# PIC32CZ2051CA80176 register map
Vendor: Microchip Technology; Series: PIC32CZCA80; File version: 0
CPU: CM7 r1p1, little endian, MPU, FPU, double-precision FPU, I-cache, D-cache, ITCM, DTCM, 3 interrupt priority bits, 222 interrupts
Registers are 32-bit, read-write, reset 0x0 unless marked. A register's access mark holds for its fields unless they carry their own. Offsets are from the block's base; [hi:lo] are bit positions; 'fields as' and 'values as' point back to an identical list.

## SUPC — Supply Controller
Base 0x44020000
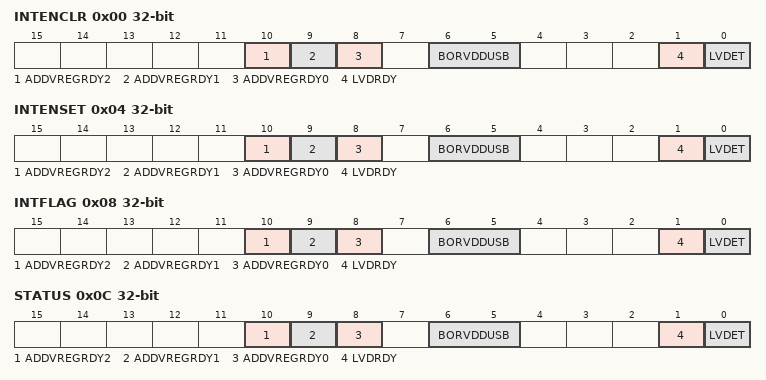
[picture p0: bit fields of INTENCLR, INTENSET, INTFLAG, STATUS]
0x00 INTENCLR write-1-clears — Interrupt Enable Clear
  [10] ADDVREGRDY2 — Additional Regulator ready 2 Interrupt Enable
  [9] ADDVREGRDY1 — Additional Regulator ready 1 Interrupt Enable
  [8] ADDVREGRDY0 — Additional Regulator ready 0 Interrupt Enable
  [6:5] BORVDDUSB — BORVDDUSB Interrupt Enable
  [1] LVDRDY — Low Voltage Detector Ready Interrupt Enable
  [0] LVDET — Low Voltage Detector Interrupt Enable
0x04 INTENSET write-1-sets — Interrupt Enable Set
  fields as INTENCLR
0x08 INTFLAG write-1-clears — Interrupt Flag Status and Clear
  [10] ADDVREGRDY2 — Additional Regulator ready 2 Interrupt. Set to one if additionnal regulator is ready meaning that output voltage is correct.
  [9] ADDVREGRDY1 — Additional Regulator ready 1 Interrupt. Set to one if additionnal regulator is ready meaning that output voltage is correct.
  [8] ADDVREGRDY0 — Additional Regulator ready 0 Interrupt. Set to one if additionnal regulator is ready meaning that output voltage is correct.
  [6:5] BORVDDUSB — BORVDDUSB Interrupt. Set to one if VDDUSB issue is detected.
  [1] LVDRDY — Low Voltage Detector Ready Interrupt. Set to one if LVD is ready to operate.
  [0] LVDET — Low Voltage Detector Interrupt. Set to one if VDDIO crosses the treshold voltage in the good direction according to LVD.DIR.
0x0C STATUS ro — Flag status
  [10] ADDVREGRDY2 — Additional Regulator ready 2 Status. One if voltage is OK. It corresponds to vreg_ready_mv signal of additional regulator.
  [9] ADDVREGRDY1 — Additional Regulator ready 1 Status. One if voltage is OK. It corresponds to vreg_ready_mv signal of additional regulator.
  [8] ADDVREGRDY0 — Additional Regulator ready 0 Status. One if voltage is OK. It corresponds to vreg_ready_mv signal of additional regulator.
  [6:5] BORVDDUSB — BORVDDUSB Status. One if VDDUSB is OK. It corresponds to bor_vddusb_n_mv signal of SMOR.
  [1] LVDRDY — Low Voltage Detector Ready Status
  [0] LVDET — Low Voltage Detector Status.
0x10 SYNCBUSY ro — Synchronisation Busy
  [0] BOR — BOR Synchronization Busy
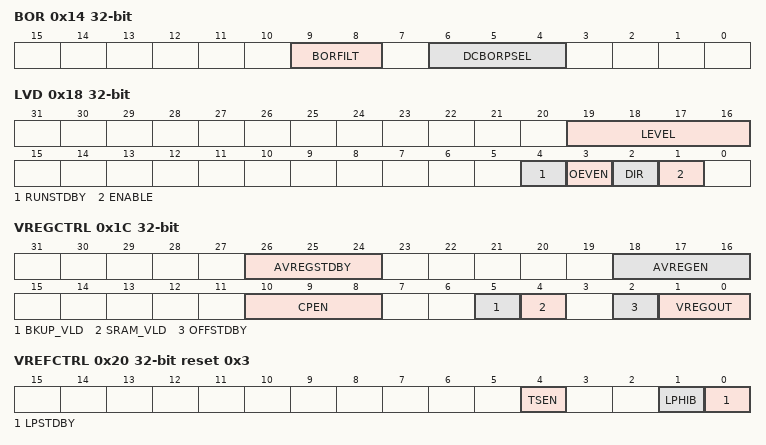
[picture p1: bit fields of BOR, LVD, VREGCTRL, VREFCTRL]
0x14 BOR — BOR Control
  [9:8] BORFILT — BOR filtering
    0=NOFILT (No digital filtering); 1=FILT32US (32us filtering); 2=FILT125US (125us filtering); 3=FILT250US (250us filtering)
  [6:4] DCBORPSEL — Duty Cycle BOR Prescaler Select
    0=NODIV (Not Divided); 1=DIV2 (Divide clock by 2); 2=DIV4 (Divide clock by 4); 3=DIV8 (Divide clock by 8); 4=DIV16 (Divide clock by 16); 5=DIV32 (Divide clock by 32); 6=DIV64 (Divide clock by 64); 7=DIV128 (Divide clock by 128)
0x18 LVD — LVD Control
  [19:16] LEVEL — Threshold Level. See 'pwr_smor_[nn]_v1 DOS' - level section to get details.
  [4] RUNSTDBY — Run during Standby
  [3] OEVEN — Output Event Enable
  [2] DIR — Direction
    0=Rising detection; 1=Falling detection
  [1] ENABLE
0x1C VREGCTRL — VREG Control
  [26:24] AVREGSTDBY — Additional Voltage Regulator Configuration
    0=OFFINSTDBY (Regulator is OFF while in sleep mode equal or deeper than standby mode. It is OFF in hibernate and backup mode as well.); 1=ONINSTDBY (Regulator is ON in Standby mode if AVREGEN bit is set. is OFF from Hibernate mode. It is OFF in backup mode as well.)
  [18:16] AVREGEN — Additional Voltage Regulator Enable
  [10:8] CPEN — Charge Pump Enable and Auto-enable.
  [5] BKUP_VLD — Backup Valid Status Bit
  [4] SRAM_VLD — SRAM Valid Status Bit
  [2] OFFSTDBY — Off in Standby Control for VREGSW[N-1]. Useful for Riverside only.
    0=OFF (In standby mode, VREGSW1,2,3 are OFF); 1=ON (In standby mode, VREGSW1,2,3 are ON)
  [1:0] VREGOUT — VREG Output Control in RUN mode only. Enable by production fuse by CALSUPC.VREGOUTEN
    0=1p2v (In Active mode, VDDCORE_RAM, VDDCORE_BU, VDDCORE_SW and optionnaly VDDCORE_PLL USB are set to 1.2v.); 1=1p0v (In Active mode, VDDCORE_RAM, VDDCORE_BU, VDDCORE_SW and optionnaly VDDCORE_PLL USB are set to 1.0v.); 2=0p8v (In Active mode, VDDCORE_RAM, VDDCORE_BU, VDDCORE_SW and optionnaly VDDCORE_PLL USB are set to 0.8v.)
0x20 VREFCTRL reset 0x3 — VREF Control
  [4] TSEN — Temperature Sensor Output Enable
  [1] LPHIB — Bandgap and Regulators Low Power Hibernate Enable
    0=FullPower (In hibernate mode, bandgap is set to nominal power mode. As a consequence, enabled regulator(s) are set to nominal power mode.); 1=LowPower (In hibernate mode, bandgap is set to low power mode. As a consequence, enabled regulator(s) are set to low power mode.)
  [0] LPSTDBY — Bandgap and Regulators Low Power Standby Enable
    0=FullPower (In standby mode, bandgap and enabled regulator(s) are set to nominal power mode.); 1=LowPower (In standby mode, bandgap and enabled regulator(s) are set to low power mode.)
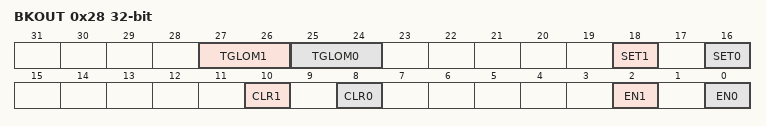
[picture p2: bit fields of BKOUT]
0x28 BKOUT — Backup Output Control
  [27:26] TGLOM1 — Toggle Output Mode
    0=DISABLE (The output does not toggle.); 1=RTCTGL (The output toggles on RTC event.); 2=BKUPTGL (The output is set when the device enters backup mode or battery backup mode. The output should then be cleared by software.)
  [25:24] TGLOM0 — Toggle Output Mode
    values as TGLOM1
  [18] SET1 — Set Output
  [16] SET0 — Set Output
  [10] CLR1 — Clear Output
  [8] CLR0 — Clear Output
  [2] EN1 — Enable Output
  [0] EN0 — Enable Output
0x2C BKIN ro — Backup Input Control
  [1:0] BKIN — Backup Input Value

## Notices in the file
Copyright (c) 2026 Microchip Technology Inc.
SPDX-License-Identifier: Apache-2.0
Licensed under the Apache License, Version 2.0 (the "License");
you may not use this file except in compliance with the License.
You may obtain a copy of the License at
http://www.apache.org/licenses/LICENSE-2.0
Unless required by applicable law or agreed to in writing, software
distributed under the License is distributed on an "AS IS" BASIS,
WITHOUT WARRANTIES OR CONDITIONS OF ANY KIND, either express or implied.
See the License for the specific language governing permissions and
limitations under the License.
